# Cortex-M1 register map
Vendor: ARM Ltd.
Cortex-M1 core descriptions, generated from ARM develloper studio
CPU: Cortex-M1 r0p0, little endian, vendor SysTick, 8 interrupt priority bits
Registers are 32-bit, read-write, no defined reset value unless marked. A register's access mark holds for its fields unless they carry their own. Offsets are from the block's base; lines under a group give offsets from that group; [hi:lo] are bit positions; {n}, {i} and the like mark numbered series; 'fields as' and 'values as' point back to an identical list; <NAME> marks a mode.

## Memory map
? SysTick size 0x80 — System Timer registers
? Control size 0xE0 — System Control registers
? ID size 0x20 — ID registers
? NVIC size 0x1A0 — Nested Vectored Interrupt Controller registers

## SysTick — System Timer registers
Base ?
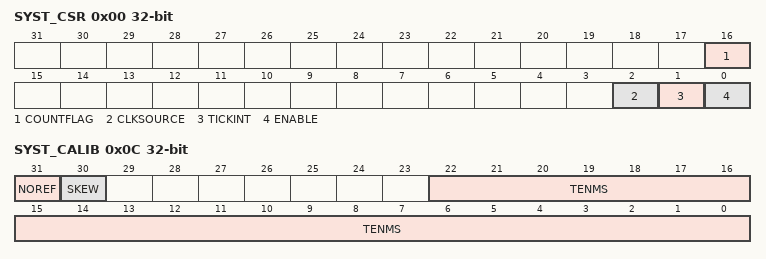
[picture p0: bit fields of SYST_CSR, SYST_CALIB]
0x00 SYST_CSR
  [16] COUNTFLAG — Indicates whether the counter has counted to 0 since the last read of this register
  [2] CLKSOURCE — Indicates the SysTick clock source
  [1] TICKINT — Indicates whether counting to 0 causes the status of the SysTick exception to change to pending
  [0] ENABLE — Indicates the enabled status of the SysTick counter
0x04 SYST_RVR
  [22:0] RELOAD — The value to load into the SYST_CVR register when the counter reaches 0
0x08 SYST_CVR
  [22:0] CURRENT — This is the value of the counter at the time it is sampled
0x0C SYST_CALIB
  [31] NOREF — Indicates whether the IMPLEMENTATION DEFINED reference clock is provided
  [30] SKEW — Indicates whether the 10ms calibration value is exact
  [22:0] TENMS — Optionally, holds a reload value to be used for 10ms (100Hz) timing, subject to system clock skew errors

## Control — System Control registers
Base ?
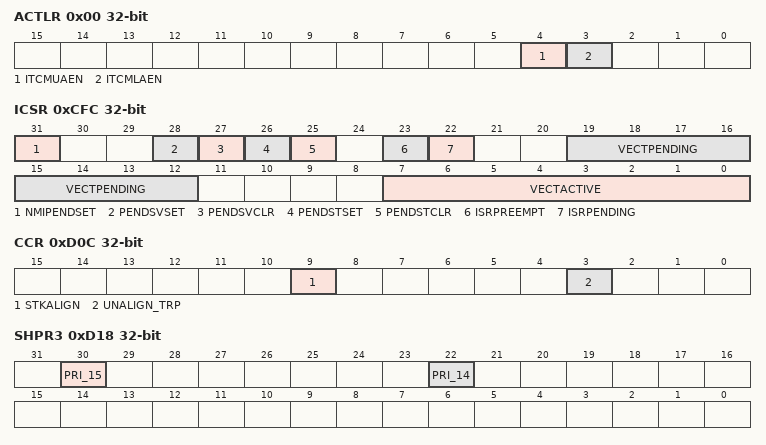
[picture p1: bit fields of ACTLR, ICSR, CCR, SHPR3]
0x00 ACTLR
  [4] ITCMUAEN — Instruction TCM Upper Alias Enable
  [3] ITCMLAEN — Instruction TCM Lower Alias Enable
0xCFC ICSR
  [31] NMIPENDSET — Activates an NMI exception or reads back the current state
  [28] PENDSVSET — Sets a pending PendSV interrupt or reads back the current state
  [27] PENDSVCLR — Clears a pending PendSV interrupt
  [26] PENDSTSET — Sets a pending SysTick or reads back the current state
  [25] PENDSTCLR — Clears a pending SysTick, whether set here or by the timer hardware
  [23] ISRPREEMPT — Indicates whether a pending exception will be serviced on exit from debug halt state
  [22] ISRPENDING — Indicates if an external configurable, NVIC generated, interrupt is pending
  [19:12] VECTPENDING — The exception number for the highest priority pending exception. 0 indicates no pending exceptions
  [7:0] VECTACTIVE — The exception number for the current executing exception
0xD04 AIRCR
  [30:16] VECTKEY — Vector Key
  [30:16] VECTKEYSTAT
  [15] ENDIANNESS — Indicates the memory system data endianness
  [2] SYSRESETREQ — System Reset Request
  [1] VECTCLRACTIVE — Clears all active state information for fixed and configurable exceptions
0xD0C CCR ro
  [9] STKALIGN — On exception entry, the SP used prior to the exception is adjusted to be 8-byte aligned and the context to restore it is saved. The SP is restored on the associated exception return
  [3] UNALIGN_TRP — Unaligned word and halfword accesses generate a HardFault exception
0xD14 SHPR2
  [30] PRI_11 — Priority of system handler 11, SVCall
0xD18 SHPR3
  [30] PRI_15 — Priority of system handler 15, SysTick
  [22] PRI_14 — Priority of system handler 14, PendSV
0xD1C SHCSR
  [15] SVCALLPENDED — This bit reflects the pending state on a read, and updates the pending state, to the value written, on a write

## ID — ID registers
Base ?
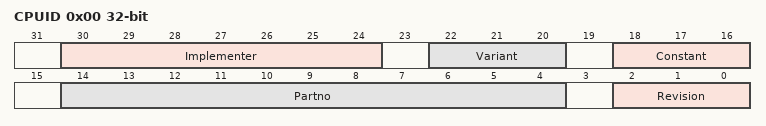
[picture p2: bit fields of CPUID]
0x00 CPUID ro
  [30:24] Implementer — Implementer code
  [22:20] Variant — Implementation defined
  [18:16] Constant — Indicates the architecture
  [14:4] Partno — Indicates part number
  [2:0] Revision — Indicates revision

## NVIC — Nested Vectored Interrupt Controller registers
Base ?
0x00 NVIC_ISER0
0x00 NVIC_ISPR0
0x80 NVIC_ICER0
0x180 NVIC_ICPR0
0x200 NVIC_IABR0
{0x300+4i} NVIC_IPR{i} (i=0..7)
